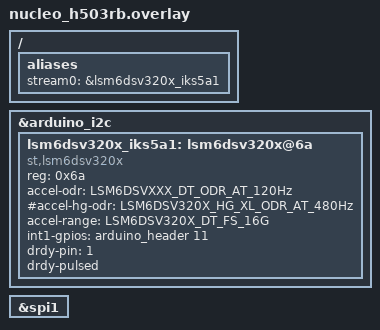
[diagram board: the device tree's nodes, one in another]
/*
 * Copyright (c) 2024 STMicroelectronics
 *
 * SPDX-License-Identifier: Apache-2.0
 */
#include <zephyr/dt-bindings/sensor/lsm6dsv320x.h>

/*
 * Nucleo F401RE board + shield iks4a1
 *
 * This devicetree overlay file will be automatically picked by the Zephyr
 * build system when building the sample for the nucleo_f401re board.
 */

/ {
	aliases {
		//stream0 = &lsm6dsv320x_spi;
		stream0 = &lsm6dsv320x_iks5a1;
	};
};

&arduino_i2c {
	#if 1
	lsm6dsv320x_iks5a1: lsm6dsv320x@6a {
		compatible = "st,lsm6dsv320x";

		reg = <0x6a>;

		accel-odr = <LSM6DSVXXX_DT_ODR_AT_120Hz>;
		#accel-hg-odr = <LSM6DSV320X_HG_XL_ODR_AT_480Hz>;
		accel-range = <LSM6DSV320X_DT_FS_16G>;

		int1-gpios =  <&arduino_header 11 GPIO_ACTIVE_HIGH>; /* D5 (PB4) */
		drdy-pin = <1>;
		drdy-pulsed;
	};
	#endif
};

&spi1 {
	#if 0
	lsm6dsv320x_spi: lsm6dsv320x@0 {
		compatible = "st,lsm6dsv320x";

		reg = <0>;
		spi-max-frequency = <DT_FREQ_M(10)>;

		accel-odr = <LSM6DSVXXX_DT_ODR_AT_480Hz>;
		accel-range = <LSM6DSV320X_DT_FS_16G>;
		gyro-odr = <LSM6DSVXXX_DT_ODR_AT_480Hz>;
		gyro-range = <LSM6DSV320X_DT_FS_500DPS>;

		int1-gpios =  <&arduino_header 5 GPIO_ACTIVE_HIGH>; /* A5 (PC0) */
		drdy-pin = <1>;
		drdy-pulsed;
	};
	#endif
};
